# trng_reva register map
Registers are read-only, no defined reset value unless marked. A register's access mark holds for its fields unless they carry their own. Offsets are from the block's base; lines under a group give offsets from that group; [hi:lo] are bit positions; {n}, {i} and the like mark numbered series; 'fields as' and 'values as' point back to an identical list; <NAME> marks a mode.

## Memory map
0x400B5000 TRNG size 0x1000 — Random Number Generator.

## Interrupts
4 TRNG — TRNG interrupt.

## TRNG — Random Number Generator.
Base 0x400B5000
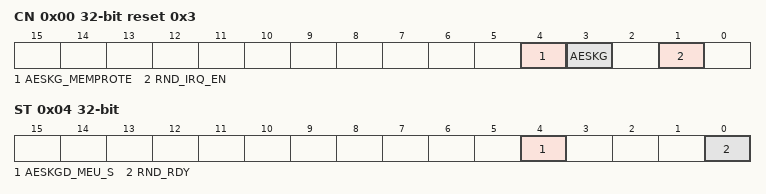
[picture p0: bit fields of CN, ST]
0x00 CN access not given reset 0x3 — TRNG Control Register.
  [4] AESKG_MEMPROTE — 128-Bit AES SPIXR Key Generate Register. Set this field to 1 to generate the 128-bit AES SPIXRkey and automatically transfer it to the AES_KEY_SPIXR registers without user intervention. This field is cleared by hardware when the key has been generated and transferred to the key registers.
    0=Normal Operation; 1=Generate Key
  [3] AESKG — 256-Bit AES NVSRAM Key Generate Register. Setting this field to 1 to generate the 256-Bit AES NVSRAM key and automatically transfer it to the AES_KEU_NVSRAM registers without user intervention. THis field is cleared by hardware when the key has been generated and transferred to the key registers.
    0=Normal Operation; 1=Generate Key
  [1] RND_IRQ_EN — To enable IRQ generation when a new 32-bit Random number is ready.
    0=disable; 1=enable
0x04 ST — TRNG Status Register.
  [4] AESKGD_MEU_S — Automatically AES transfer on going
  [0] RND_RDY — 32-bit random data is ready to read from TRNG_DATA register. Reading TRNG_DATA when RND_RDY=0 will return all 0's. IRQ is generated when RND_RDY=1 if TRNG_CN.RND_IRQ_EN=1.
    0=Busy (TRNG Busy); 1=Ready (32 bit random data is ready)
0x08 DATA — TRNG Data Register.
  [31:0] DATA — Data. The content of this register is valid only when RNG_IS =1. When TNRG is disabled, read returns 0x0000 0000.
